# LPC13Uxx register map
File version: 1
LPC1315/16/17/35/36/37 Cortex-M3 MCU; up to 64 kB flash; up to 12 kB SRAM; USB device; USART; EEPROM
CPU: CM3 r2p1, little endian, no MPU, no FPU, 3 interrupt priority bits
Registers are 32-bit, read-write, reset 0x0 unless marked. A register's access mark holds for its fields unless they carry their own. Offsets are from the block's base; lines under a group give offsets from that group; [hi:lo] are bit positions; {n}, {i} and the like mark numbered series; 'fields as' and 'values as' point back to an identical list; <NAME> marks a mode.

## Memory map
0x40000000 I2C size 0xFFF
0x40004000 WWDT size 0xFFF — Windowed Watchdog Timer (WWDT)
0x40008000 USART size 0xFFF
0x4000C000 CT16B0 size 0xFFF — 16-bit counter/timers CT16B0
0x40010000 CT16B1 size 0xFFF — 16-bit counter/timers CT16B1
0x40014000 CT32B0 size 0xFFF — 32-bit counter/timers CT32B0
0x40018000 CT32B1 size 0xFFF — 32-bit counter/timers CT32B1
0x4001C000 ADC size 0xFFF
0x40038000 PMU size 0xFFF — Power Management Unit (PMU)
0x4003C000 FLASHCTRL size 0xFFF — Flash programming firmware
0x40040000 SSP0 size 0xFFF — SSP/SPI
0x40044000 IOCON size 0xFFF — IO ocnfiguration
0x40048000 SYSCON size 0xFFF — System control block
0x4004C000 GPIO_PIN_INT size 0xFFF — GPIO pin interrupt
0x40058000 SSP1 size 0xFFF
0x4005C000 GPIO_GROUP_INT0 size 0xFFF — GPIO group interrupt
0x40060000 GPIO_GROUP_INT1 size 0xFFF
0x40064000 RITIMER size 0xFFF — Repetitive Interrupt Timer (RI timer)
0x40080000 USB size 0xFFF — USB2.0 device controller
0x50000000 GPIO_PORT size 0xFFFFF

## Interrupts
{n} PIN_INT{n} (GPIO_PIN_INT) (n=0..7)
8 GINT0 (GPIO_GROUP_INT0)
9 GINT1 (GPIO_GROUP_INT1)
12 RIT_IRQ (RITIMER)
14 SSP1
15 I2C
16 CT16B0
17 CT16B1
18 CT32B0
19 CT32B1
20 SSP0
21 USART
22 USB_IRQ (USB)
23 USB_FIQ (USB)
24 ADC
25 WWDT
26 BOD_IRQ (SYSCON)
27 FLASH_IRQ (FLASHCTRL)
30 USBWAKEUP (USB)

## PMU — Power Management Unit (PMU)
Base 0x40038000
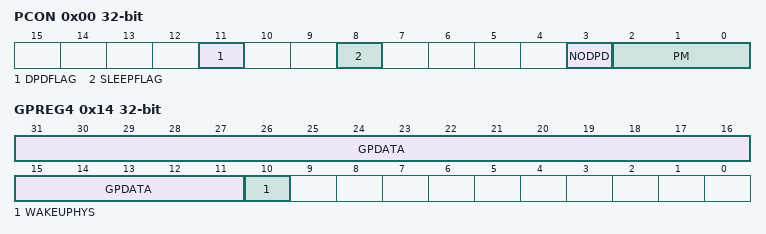
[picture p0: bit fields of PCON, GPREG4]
0x00 PCON — Power control register
  [11] DPDFLAG — Deep power-down flag
    0=DPNOTENTERED (Read: Deep power-down mode not entered. Write: No effect.); 1=DPENTERED (Read: Deep power-down mode entered. Write: Clear the Deep power-down flag.)
  [8] SLEEPFLAG — Sleep mode flag
    0=NOPOWERDOWN (Read: No power-down mode entered. LPC11U1x is in Active mode. Write: No effect.); 1=POWERDOWN (Read: Sleep/Deep-sleep or Deep power-down mode entered. Write: Writing a 1 clears the SLEEPFLAG bit to 0.)
  [3] NODPD — A 1 in this bit prevents entry to Deep power-down mode when 0x3 is written to the PM field above, the SLEEPDEEP bit is set, and a WFI is executed. Execution continues after the WFI if this bit is 1. This bit is cleared only by power-on reset, so writing a one to this bit locks the part in a mode in which Deep power-down mode is blocked.
  [2:0] PM — Power mode
    0=DEFAULT (Default. The part is in active or sleep mode.); 1=DEEPSLEEP (ARM WFI will enter Deep-sleep mode.); 2=POWERDOWN (ARM WFI will enter Power-down mode.); 3=DEEPPOWERDOWN (ARM WFI will enter Deep-power down mode (ARM Cortex-M0 core powered-down).)
{0x4+4i} GPREG{i} (i=0..3) — General purpose register 0
  [31:0] GPDATA — Data retained during Deep power-down mode.
0x14 GPREG4 — General purpose register 4
  [31:11] GPDATA — Data retained during Deep power-down mode.
  [10] WAKEUPHYS — WAKEUP pin hysteresis enable
    0=DISABLED (Hysteresis for WAKEUP pin disabled.); 1=ENABLED (Hysteresis for WAKEUP pin enabled.)

## GPIO_PIN_INT — GPIO pin interrupt
Base 0x4004C000
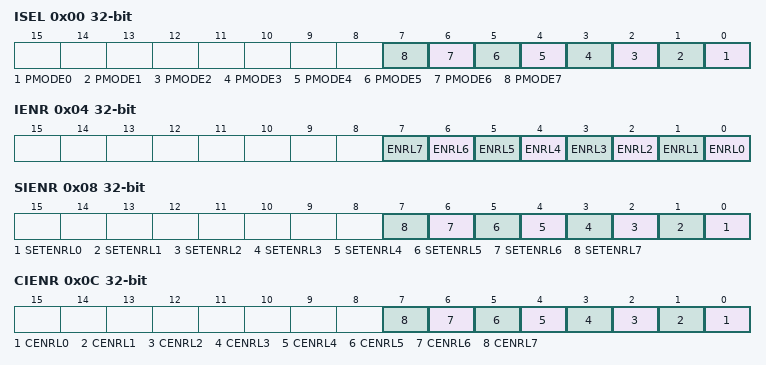
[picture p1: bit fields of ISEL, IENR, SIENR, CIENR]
0x00 ISEL — Pin Interrupt Mode register
  [n] PMODE{n} (n=0..7) — Selects the interrupt mode for each pin interrupt. Bit n configures the pin interrupt selected in PINTSELn. 0 = Edge sensitive 1 = Level sensitive
0x04 IENR — Pin Interrupt Enable (Rising) register
  [n] ENRL{n} (n=0..7) — Enables the rising edge or level interrupt for each pin interrupt. Bit n configures the pin interrupt selected in PINTSELn. 0 = Disable rising edge or level interrupt. 1 = Enable rising edge or level interrupt.
0x08 SIENR wo reset not defined — Set Pin Interrupt Enable (Rising) register
  [n] SETENRL{n} (n=0..7) — Ones written to this address set bits in the PINTEN_R, thus enabling interrupts. Bit n sets bit n in the PINTEN_R register. 0 = No operation. 1 = Enable rising edge or level interrupt.
0x0C CIENR wo reset not defined — Clear Pin Interrupt Enable (Rising) register
  [n] CENRL{n} (n=0..7) — Ones written to this address clear bits in the IENR, thus disabling the interrupts. Bit n clears bit n in the IENR register. 0 = No operation. 1 = Disable rising edge or level interrupt.
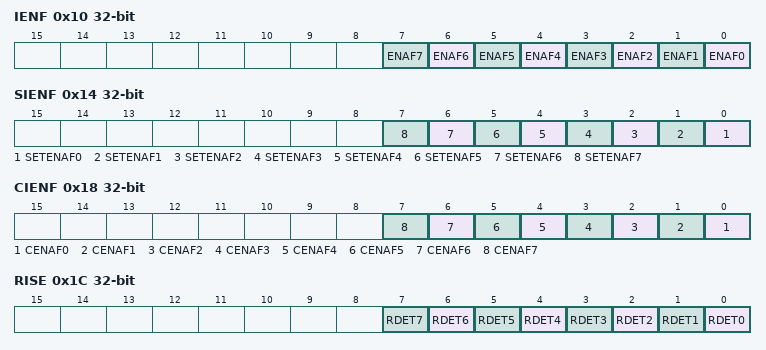
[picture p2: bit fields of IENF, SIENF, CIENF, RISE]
0x10 IENF — Pin Interrupt Enable Falling Edge / Active Level register
  [n] ENAF{n} (n=0..7) — Enables the falling edge or configures the active level interrupt for each pin interrupt. Bit n configures the pin interrupt selected in PINTSELn. 0 = Disable falling edge interrupt or set active interrupt level LOW. 1 = Enable falling edge interrupt enabled or set active interrupt level HIGH.
0x14 SIENF wo reset not defined — Set Pin Interrupt Enable Falling Edge / Active Level register
  [n] SETENAF{n} (n=0..7) — Ones written to this address set bits in the IENF, thus enabling interrupts. Bit n sets bit n in the IENF register. 0 = No operation. 1 = Select HIGH-active interrupt or enable falling edge interrupt.
0x18 CIENF wo reset not defined — Clear Pin Interrupt Enable Falling Edge / Active Level address
  [n] CENAF{n} (n=0..7) — Ones written to this address clears bits in the IENF, thus disabling interrupts. Bit n clears bit n in the IENF register. 0 = No operation. 1 = LOW-active interrupt selected or falling edge interrupt disabled.
0x1C RISE — Pin Interrupt Rising Edge register
  [n] RDET{n} (n=0..7) — Rising edge detect. Bit n detects the rising edge of the pin selected in PINTSELn. Read 0: No rising edge has been detected on this pin since Reset or the last time a one was written to this bit. Write 0: no operation. Read 1: a rising edge has been detected since Reset or the last time a one was written to this bit. Write 1: clear rising edge detection for this pin.
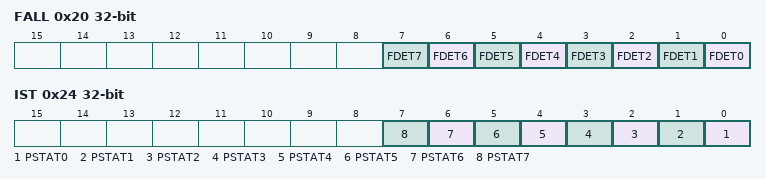
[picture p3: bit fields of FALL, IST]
0x20 FALL — Pin Interrupt Falling Edge register
  [n] FDET{n} (n=0..7) — Falling edge detect. Bit n detects the falling edge of the pin selected in PINTSELn. Read 0: No falling edge has been detected on this pin since Reset or the last time a one was written to this bit. Write 0: no operation. Read 1: a falling edge has been detected since Reset or the last time a one was written to this bit. Write 1: clear falling edge detection for this pin.
0x24 IST — Pin Interrupt Status register
  [n] PSTAT{n} (n=0..7) — Pin interrupt status. Bit n returns the status, clears the edge interrupt, or inverts the active level of the pin selected in PINTSELn. Read 0: interrupt is not being requested for this interrupt pin. Write 0: no operation. Read 1: interrupt is being requested for this interrupt pin. Write 1 (edge-sensitive): clear rising- and falling-edge detection for this pin. Write 1 (level-sensitive): switch the active level for this pin (in the PINTENT_F register).
